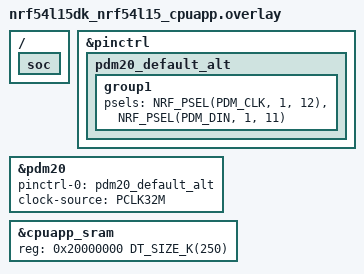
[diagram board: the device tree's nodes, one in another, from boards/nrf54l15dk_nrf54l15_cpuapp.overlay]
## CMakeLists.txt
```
# SPDX-License-Identifier: Apache-2.0

cmake_minimum_required(VERSION 3.20.0)
find_package(Zephyr REQUIRED HINTS $ENV{ZEPHYR_BASE})
project(bap_unicast_server_nrf54l15)

target_sources(app PRIVATE
  src/main.c
  src/ml_main.cc
  src/mfcc_data.c
  src/kws_model_data.cc
  src/cpu_based_blocks.cc
)

zephyr_library_include_directories(${ZEPHYR_BASE}/samples/bluetooth)
```

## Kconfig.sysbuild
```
# Copyright 2023 Nordic Semiconductor ASA
# SPDX-License-Identifier: Apache-2.0

source "share/sysbuild/Kconfig"

config NET_CORE_BOARD
	string
	default "nrf5340dk/nrf5340/cpunet" if "$(BOARD)" = "nrf5340dk"
	default "nrf5340_audio_dk/nrf5340/cpunet" if "$(BOARD)" = "nrf5340_audio_dk"
	default "nrf5340bsim/nrf5340/cpunet" if $(BOARD_TARGET_STRING) = "NRF5340BSIM_NRF5340_CPUAPP"

config NET_CORE_IMAGE_HCI_IPC
	bool "HCI IPC image on network core"
	default y
	depends on NET_CORE_BOARD != ""
```

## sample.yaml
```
sample:
  description: Bluetooth Low Energy Audio Unicast Server sample
  name: Bluetooth Low Energy Audio Unicast Server sample
tests:
  sample.bluetooth.audio_unicast_server:
    harness: bluetooth
    platform_allow:
      - qemu_cortex_m3
      - qemu_x86
      - nrf5340bsim/nrf5340/cpuapp
      - nrf5340dk/nrf5340/cpuapp
      - native_sim
    tags: bluetooth
    integration_platforms:
      - nrf5340dk/nrf5340/cpuapp
    sysbuild: true
  sample.bluetooth.audio_unicast_server.bt_ll_sw_split:
    harness: bluetooth
    platform_allow:
      - nrf52_bsim
      - nrf52dk/nrf52832
      - nrf52840dk/nrf52840
    integration_platforms:
      - nrf52dk/nrf52832
    extra_args:
      - OVERLAY_CONFIG=overlay-bt_ll_sw_split.conf
      - SNIPPET="bt-ll-sw-split"
    tags: bluetooth
```

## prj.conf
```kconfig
CONFIG_AUDIO_DMIC=y
CONFIG_AUDIO=y
CONFIG_BT=y
CONFIG_LOG=y
CONFIG_BT_PERIPHERAL=y
CONFIG_BT_ISO_PERIPHERAL=y
CONFIG_BT_AUDIO=y
CONFIG_BT_BAP_UNICAST_SERVER=y
CONFIG_BT_ASCS=y
CONFIG_BT_ASCS_MAX_ASE_SNK_COUNT=1
CONFIG_BT_ASCS_MAX_ASE_SRC_COUNT=1
CONFIG_BT_ISO_TX_BUF_COUNT=16
# Support an ISO channel per ASE
CONFIG_BT_ISO_MAX_CHAN=2

CONFIG_BT_AUDIO_CODEC_CFG_MAX_METADATA_SIZE=80

# Mandatory to support at least 1 for ASCS
CONFIG_BT_ATT_PREPARE_COUNT=8
CONFIG_BT_GATT_DYNAMIC_DB=y
CONFIG_BT_EXT_ADV=y
CONFIG_BT_DEVICE_NAME="nrf54l15_pdm_mic"
CONFIG_SW_CODEC_LC3_T2_SOFTWARE=y
CONFIG_FPU=y
CONFIG_NEWLIB_LIBC=y
CONFIG_BT_LOG_SNIFFER_INFO=y
CONFIG_THREAD_NAME=y
CONFIG_CLOCK_CONTROL=y
CONFIG_LC3_ENC_CHAN_MAX=1
CONFIG_BT_BONDABLE=y
CONFIG_BT_SMP=y
CONFIG_LOG_BUFFER_SIZE=4096

# Enable DK LED and Buttons library
CONFIG_DK_LIBRARY=y
CONFIG_BT_SECURITY_ERR_TO_STR=y
CONFIG_BT_SMP_ERR_TO_STR=y

CONFIG_BT_MAX_CONN=2
CONFIG_BT_ATT_TX_COUNT=5
CONFIG_BT_BAS=y
CONFIG_BT_HIDS=y
CONFIG_BT_HIDS_MAX_CLIENT_COUNT=2
CONFIG_BT_HIDS_DEFAULT_PERM_RW_ENCRYPT=y
CONFIG_BT_GATT_UUID16_POOL_SIZE=40
CONFIG_BT_GATT_CHRC_POOL_SIZE=20
CONFIG_BT_CONN_CTX=y
CONFIG_BT_DIS=y
CONFIG_BT_DIS_MANUF_NAME=y
CONFIG_BT_DIS_MANUF_NAME_STR="NordicSemiconductor"
CONFIG_BT_DIS_PNP=y
CONFIG_BT_DIS_PNP_VID_SRC=2
CONFIG_BT_DIS_PNP_VID=0x1915
CONFIG_BT_DIS_PNP_PID=0xEEEE
CONFIG_BT_DIS_PNP_VER=0x0100


CONFIG_MAIN_STACK_SIZE=2048
CONFIG_SYSTEM_WORKQUEUE_STACK_SIZE=2048

CONFIG_BT_SETTINGS=y
CONFIG_FLASH=y
CONFIG_FLASH_MAP=y
CONFIG_NVS=y
CONFIG_SETTINGS=y

CONFIG_GPIO=y
```

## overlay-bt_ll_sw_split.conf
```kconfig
CONFIG_BT_LL_SW_SPLIT=y
CONFIG_BT_CTLR_ADV_DATA_LEN_MAX=191
CONFIG_BT_CTLR_ISO_TX_BUFFERS=2
CONFIG_BT_CTLR_ISOAL_SOURCES=1
CONFIG_BT_CTLR_ISOAL_SINKS=2

# Support the highest SDU size required by any BAP LC3 presets (155) + 8 bytes of HCI ISO Data
# packet overhead (the Packet_Sequence_Number, ISO_SDU_Length, Packet_Status_Flag fields; and
# the optional Time_Stamp field, if supplied)
CONFIG_BT_CTLR_ISO_TX_BUFFER_SIZE=163

# Use the below if the sample is sending stale packet sequence number
# CONFIG_BT_CTLR_ADVANCED_FEATURES=y
# CONFIG_BT_CTLR_ISOAL_SN_STRICT=n
```

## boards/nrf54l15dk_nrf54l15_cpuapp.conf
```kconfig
# For LC3 the following configs are needed
CONFIG_FPU=y
#CONFIG_LIBLC3=y
# The LC3 codec uses a large amount of stack. This app runs the codec in the work-queue, hence
# inctease stack size for that thread.
CONFIG_SYSTEM_WORKQUEUE_STACK_SIZE=8192

CONFIG_BT_BUF_EVT_RX_SIZE=255
CONFIG_BT_BUF_ACL_RX_SIZE=255
CONFIG_BT_BUF_ACL_TX_SIZE=251
CONFIG_BT_BUF_CMD_TX_SIZE=255

# KCONFIG for KWS
CONFIG_MAIN_STACK_SIZE=8192
CONFIG_RING_BUFFER=y
CONFIG_CPP=y
CONFIG_STD_CPP17=y
CONFIG_NEWLIB_LIBC=y
CONFIG_REQUIRES_FULL_LIBCPP=y
CONFIG_CBPRINTF_FP_SUPPORT=y
CONFIG_FPU=y
CONFIG_LOG=y
CONFIG_LOG_MODE_IMMEDIATE=y
CONFIG_PRINTK=y
CONFIG_PRINTK_SYNC=y
CONFIG_CMSIS_NN=y
CONFIG_CMSIS_NN_ACTIVATION=y
CONFIG_CMSIS_NN_BASICMATH=y
CONFIG_CMSIS_NN_CONCATENATION=y
CONFIG_CMSIS_NN_CONVOLUTION=y
CONFIG_CMSIS_NN_FULLYCONNECTED=y
CONFIG_CMSIS_NN_NNSUPPORT=y
CONFIG_CMSIS_NN_POOLING=y
CONFIG_CMSIS_NN_RESHAPE=y
CONFIG_CMSIS_NN_SOFTMAX=y
CONFIG_CMSIS_NN_SVD=y
CONFIG_CMSIS_NN_LSTM=y

#enable CMSIS MFCC
CONFIG_FPU=y
CONFIG_CMSIS_DSP=y
CONFIG_CMSIS_DSP_BASICMATH=y
CONFIG_CMSIS_DSP_COMPLEXMATH=y
CONFIG_CMSIS_DSP_FASTMATH=y
CONFIG_CMSIS_DSP_FILTERING=y
CONFIG_CMSIS_DSP_MATRIX=y
CONFIG_CMSIS_DSP_STATISTICS=y
CONFIG_CMSIS_DSP_TRANSFORM=y
CONFIG_CMSIS_DSP_DISTANCE=y
CONFIG_CMSIS_DSP_WINDOW=y

CONFIG_CMSIS_DSP_LOOPUNROLL=y

CONFIG_REQUIRES_FLOAT_PRINTF=y

CONFIG_TENSORFLOW_LITE_MICRO=y
CONFIG_TENSORFLOW_LITE_MICRO_CMSIS_NN_KERNELS=y
```

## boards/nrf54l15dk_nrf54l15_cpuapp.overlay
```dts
/*
 * Copyright (c) 2024 Nordic Semiconductor ASA
 *
 * SPDX-License-Identifier: Apache-2.0
 */

&pinctrl {
	pdm20_default_alt: pdm20_default_alt {
		group1 {
			psels = <NRF_PSEL(PDM_CLK, 1, 12)>,
				<NRF_PSEL(PDM_DIN, 1, 11)>;
		};
	};
};

dmic_dev: &pdm20 {
	status = "okay";
	pinctrl-0 = <&pdm20_default_alt>;
	pinctrl-names = "default";
	clock-source = "PCLK32M";
};

&cpuapp_sram {
	reg = <0x20000000 DT_SIZE_K(250)>;
	ranges = <0x0 0x20000000 DT_SIZE_K(250)>;
};

/{
	soc {
		/delete-node/ cpuflpr_sram;
	};

};
```

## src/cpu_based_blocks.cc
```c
#include <zephyr/kernel.h>
#include <stdio.h>
#include <string.h>
#include <stdarg.h>

#include <dsp/transform_functions.h>
#include <dsp/statistics_functions.h>
#include <dsp/basic_math_functions.h>
#include <dsp/complex_math_functions.h>
#include <dsp/fast_math_functions.h>
#include <dsp/matrix_functions.h>
#include "mfcc_data.h"

#include <tensorflow/lite/micro/micro_mutable_op_resolver.h>
#include <tensorflow/lite/micro/micro_log.h>
#include <tensorflow/lite/micro/micro_interpreter.h>
#include <tensorflow/lite/micro/system_setup.h>
#include <tensorflow/lite/schema/schema_generated.h>
#include "kws_model_data.h"

#include <zephyr/logging/log.h>
#define LOG_LEVEL 2
LOG_MODULE_DECLARE(dmic_sample);


#include <math.h>

static arm_mfcc_instance_f32 S_mfcc;
static float cmsis_mfcc_input[512]; // hold mfcc input
float cmsis_mfcc_tmp[1024]; // tmp buffer to mfcc

const tflite::Model *model = nullptr;
tflite::MicroInterpreter *interpreter = nullptr;
TfLiteTensor *input = nullptr;
TfLiteTensor *output = nullptr;
float input_scale, output_scale;
int input_zp, output_zp;
constexpr int kTensorArenaSize = 30000;
uint8_t tensor_arena[kTensorArenaSize];



inline void arm_mfcc_f32_modified(
	const arm_mfcc_instance_f32 * S,
	float32_t *pSrc,
	float32_t *pDst,
	float32_t *pTmp
	)
{

	// float32_t maxValue;
	// uint32_t  index;
	uint32_t i;
	float32_t result;
	const float32_t *coefs=S->filterCoefs;
	arm_matrix_instance_f32 pDctMat;

	/* Normalize */
	// arm_absmax_f32(pSrc,S->fftLen,&maxValue,&index);

	// if (maxValue != 0.0f)
	// {
	//    arm_scale_f32(pSrc,1.0f/maxValue,pSrc,S->fftLen);
	// }

	/* Multiply by window */
	arm_mult_f32(pSrc,S->windowCoefs,pSrc,S->fftLen);

	/* Compute spectrum magnitude
	*/
#if defined(ARM_MFCC_CFFT_BASED)
	/* some HW accelerator for CMSIS-DSP used in some boards
		are only providing acceleration for CFFT.
		With ARM_MFCC_CFFT_BASED enabled, CFFT is used and the MFCC
		will be accelerated on those boards.

		The default is to use RFFT
	*/
	/* Convert from real to complex */
	for(i=0; i < S->fftLen ; i++)
	{
		pTmp[2*i] = pSrc[i];
		pTmp[2*i+1] = 0.0f;
	}
	arm_cfft_f32(&(S->cfft),pTmp,0,1);
#else
	/* Default RFFT based implementation */
	arm_rfft_fast_f32(&(S->rfft),pSrc,pTmp,0);
	/* Unpack real values */
	pTmp[S->fftLen]=pTmp[1];
	pTmp[S->fftLen+1]=0.0f;
	pTmp[1]=0.0f;
#endif
	// Shouldn't the length be S->fftLen + 2 (=514) or 257 complex points ?
	arm_cmplx_mag_f32(pTmp,pSrc,(S->fftLen + 2)/2);
	// if (maxValue != 0.0f)
	// {
	//    arm_scale_f32(pSrc,maxValue,pSrc,S->fftLen);
	// }

	/* Apply MEL filters */
	for(i=0; i<S->nbMelFilters; i++)
	{
		arm_dot_prod_f32(pSrc+S->filterPos[i],
			coefs,
			S->filterLengths[i],
			&result);

		coefs += S->filterLengths[i];

		pTmp[i] = result;

	}

	/* Compute the log */
	arm_offset_f32(pTmp,1.0e-6f,pTmp,S->nbMelFilters);
	arm_vlog_f32(pTmp,pTmp,S->nbMelFilters);

	/* Multiply with the DCT matrix */
	pDctMat.numRows=S->nbDctOutputs;
	pDctMat.numCols=S->nbMelFilters;
	pDctMat.pData=(float32_t*)S->dctCoefs;

	arm_mat_vec_mult_f32(&pDctMat, pTmp, pDst);
}




int cpu_blocks_init(void) {
	uint32_t start, end;


	arm_mfcc_init_f32(&S_mfcc,
		512,
		40,
		10,
		mfcc_dct_coefs_config1_f32,
		mfcc_filter_pos_config1_f32,
		mfcc_filter_len_config1_f32,
		mfcc_filter_coefs_config1_f32,
		mfcc_window_coefs_config1_f32);

	model = tflite::GetModel(kws_model_data);
	if (model->version() != TFLITE_SCHEMA_VERSION) {
		MicroPrintf("Model provided is schema version %d not equal "
					"to supported version %d.",
					model->version(), TFLITE_SCHEMA_VERSION);
		return 1;
	}
	static tflite::MicroMutableOpResolver <6> micro_op_resolver;
	micro_op_resolver.AddFullyConnected();
    micro_op_resolver.AddAveragePool2D();
    micro_op_resolver.AddConv2D();
    micro_op_resolver.AddDepthwiseConv2D();
    micro_op_resolver.AddReshape();
    micro_op_resolver.AddSoftmax();

	static tflite::MicroInterpreter static_interpreter(
		model, micro_op_resolver, tensor_arena, kTensorArenaSize);
	interpreter = &static_interpreter;

	/* Allocate memory from the tensor_arena for the model's tensors. */
	TfLiteStatus allocate_status = interpreter->AllocateTensors();
	if (allocate_status != kTfLiteOk) {
		MicroPrintf("AllocateTensors() failed");
		return 1;
	}

	/* Obtain pointers to the model's input and output tensors. */
	input = interpreter->input(0);
	output = interpreter->output(0);



	input_scale = ((TfLiteAffineQuantization*)input->quantization.params)->scale->data[0];
	input_zp = ((TfLiteAffineQuantization*)input->quantization.params)->zero_point->data[0];

	output_scale = ((TfLiteAffineQuantization*)output->quantization.params)->scale->data[0];
	output_zp = ((TfLiteAffineQuantization*)output->quantization.params)->zero_point->data[0];

	printk("input tensor quant spec: zero point = %d, scale = %f\n", input_zp, input_scale);
	printk("output tensor quant spec: zero point = %d, scale = %f\n", output_zp, output_scale);

	return 0;
}

void mfcc_cpu(const int16_t* audio_sample, int8_t* mfcc_result) {
    float mfcc_slice[10];

	for (int i = 0; i < 480; i++) {
		cmsis_mfcc_input[i] = audio_sample[i] / 32768.0f;
	}
	arm_mfcc_f32_modified(&S_mfcc, cmsis_mfcc_input, mfcc_slice, cmsis_mfcc_tmp);

	/* Quantize based on input tensor spec */
	for (int j = 0; j < 10; j++) {
		int32_t tmp;
		// tmp = static_cast<int32_t>(mfcc_slice[j] / input_scale) + input_zp;
		tmp = static_cast<int32_t>(round(mfcc_slice[j] / input_scale)) + input_zp;
		if (tmp > INT8_MAX) {
			mfcc_result[j] = INT8_MAX;
			LOG_INF("too large! %d\n", tmp);
		} else if (tmp < INT8_MIN) {
			mfcc_result[j] = INT8_MIN;
			LOG_INF("too small! %d\n", tmp);
		} else {
			mfcc_result[j] = static_cast<int8_t>(tmp);
		}
	}

}

void inference_cpu(const int8_t* mfcc_feature_map, int* class_index) {

	uint32_t start, end;
	start = k_uptime_get_32();
	TfLiteStatus invoke_status = kTfLiteOk;

	for (int i = 0; i < 490; i++) {
		(input->data.int8)[i] = mfcc_feature_map[i];
	}

	invoke_status = interpreter->Invoke();
	end = k_uptime_get_32();
	// printk("Time used for inference: %d ms.\n", end - start);
	if (invoke_status != kTfLiteOk) {
		printk("Invoke failed\n");
		return;
	}

	/* Retrieve result */
	int max_idx = 0;
	for (int i = 0; i < 12; i++) {
		if (output->data.int8[max_idx] < output->data.int8[i]) {
			max_idx = i;
		}
	}
	*class_index = max_idx;

	return;
}
```

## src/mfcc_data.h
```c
#ifndef _MFCC_DATA_H_
#define _MFCC_DATA_H_ 

#include "arm_math_types.h"


#ifdef   __cplusplus
extern "C"
{
#endif


/*****

 DCT COEFFICIENTS FOR THE MFCC

*****/


#define NB_MFCC_DCT_COEFS_CONFIG1_F32 400
extern const float32_t mfcc_dct_coefs_config1_f32[NB_MFCC_DCT_COEFS_CONFIG1_F32];



/*****

 WINDOW COEFFICIENTS

*****/


#define NB_MFCC_WIN_COEFS_CONFIG1_F32 512
extern const float32_t mfcc_window_coefs_config1_f32[NB_MFCC_WIN_COEFS_CONFIG1_F32];



/*****

 MEL FILTER COEFFICIENTS FOR THE MFCC

*****/

#define NB_MFCC_NB_FILTER_CONFIG1_F32 40
extern const uint32_t mfcc_filter_pos_config1_f32[NB_MFCC_NB_FILTER_CONFIG1_F32];
extern const uint32_t mfcc_filter_len_config1_f32[NB_MFCC_NB_FILTER_CONFIG1_F32];





#define NB_MFCC_FILTER_COEFS_CONFIG1_F32 247
extern const float32_t mfcc_filter_coefs_config1_f32[NB_MFCC_FILTER_COEFS_CONFIG1_F32];



#ifdef   __cplusplus
}
#endif

#endif
```

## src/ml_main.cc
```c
#include <zephyr/kernel.h>
#include <stdio.h>
#include <string.h>
#include <stdarg.h>
#include <zephyr/sys/ring_buffer.h>
#include <math.h>
#include <dk_buttons_and_leds.h>

#include "ml_main.h"

#define SAMPLE_LENGTH_IN_MS 100
#define PDM_BYTE_DEPTH 2
#define PDM_SAMPLE_PER_SEC 16000

extern void cpu_blocks_init(void);
extern void mfcc_cpu(const int16_t* audio_sample, int8_t* mfcc_result);
extern void inference_cpu(const int8_t* mfcc_feature_map, int* class_index);



#define MFCC_STEP_IN_MS 20
#define MFCC_WINDOW_IN_MS 30

/*
 * Local buffer to copy data from PDM buffer. Extra space for data corrsponding one MFCC window
 * is added to hold residual part
 */

static int16_t mfcc_input[PDM_SAMPLE_PER_SEC*SAMPLE_LENGTH_IN_MS/MSEC_PER_SEC+PDM_SAMPLE_PER_SEC*MFCC_WINDOW_IN_MS/MSEC_PER_SEC];


#define MFCC_RING_BUF_BYTES 1000
RING_BUF_DECLARE(mfcc_int8_ring_buf, MFCC_RING_BUF_BYTES);

/* Semephore to sync mfcc calculation and kws inference. */
/* It's binary as we let the inference workflow to determine how many rounds of inference should happen */
K_SEM_DEFINE(mfcc_ready, 0 ,1);

#define MFCC_DATA_LENGTH 10
#define KWS_MFCC_WINDOW 49
#define KWS_MFCC_STEP 10
int8_t inference_input[KWS_MFCC_WINDOW*MFCC_DATA_LENGTH];

const char* label[] = {"Down", "Go", "Left", "No", "Off", "On", "Right", "Stop", "Up", "Yes", "Silence", "Unknown"};

#define INFERENCE_STACK_SIZE 4096
#define INFERENCE_PRIORITY 5

void inference_thread(void *, void *, void *) {
#define FILTER_WINDOW_LEN 4
	int last_n_results[FILTER_WINDOW_LEN];
	for (int i = 0; i < FILTER_WINDOW_LEN; i++) {
				last_n_results[i] = -1;
	}
	while (true) {

		k_sem_take(&mfcc_ready, K_FOREVER);
		while (ring_buf_size_get(&mfcc_int8_ring_buf) >= MFCC_DATA_LENGTH * KWS_MFCC_WINDOW) {
			int max_idx = 0;
			ring_buf_peek(&mfcc_int8_ring_buf, (uint8_t*)inference_input, MFCC_DATA_LENGTH * KWS_MFCC_WINDOW);


			inference_cpu(inference_input, &max_idx);



			// printk("[%u] Label: %s, likelihood %f\n",end, label[max_idx],
			// 	output_scale * (output->data.int8[max_idx] - output_zp));
			for (int i = 0; i < FILTER_WINDOW_LEN - 1; i++) {
				last_n_results[i] = last_n_results[i+1];
			}
			last_n_results[FILTER_WINDOW_LEN - 1] = max_idx;
			bool all_same = true;
			for (int i = 0; i < FILTER_WINDOW_LEN - 1; i++) {
				if (last_n_results[i] != last_n_results[i+1]) {
					all_same = false;
					break;
				}
			}
			if (all_same == true) {
				printk("Label: %s in last %d inferences.\n", label[max_idx], FILTER_WINDOW_LEN);
				if (max_idx == 4) {
					dk_set_led_off(DK_LED4);
				}
				if (max_idx == 5) {
					dk_set_led_on(DK_LED4);
				}
				for (int i = 0; i < FILTER_WINDOW_LEN; i++) {
					last_n_results[i] = -1;
				}
			}

			/* How many data we remove determines how frequency the inference is */
			/* Every step length of 1 equal to 20 ms */
			ring_buf_get(&mfcc_int8_ring_buf, NULL, KWS_MFCC_STEP*MFCC_DATA_LENGTH);

		}

	}

}

K_THREAD_STACK_DEFINE(inference_stack_area, INFERENCE_STACK_SIZE);
struct k_thread inference_thread_data;

uint32_t mfcc_input_tail;

int ml_init(void) {
	cpu_blocks_init();

	/*start inference thread*/
	k_tid_t my_tid = k_thread_create(&inference_thread_data, inference_stack_area,
                                 K_THREAD_STACK_SIZEOF(inference_stack_area),
                                 inference_thread,
                                 NULL, NULL, NULL,
                                 INFERENCE_PRIORITY, 0, K_NO_WAIT);
	printk("inference thread id %d\n", my_tid);

	mfcc_input_tail = 0;
	return 0;
}
int ml_process(void* buffer, size_t size) {


	int sample_len;

	sample_len = size / 2;

	for (int i = 0; i < sample_len; i++) {
		mfcc_input[mfcc_input_tail] = ((int16_t*)buffer)[i];
		mfcc_input_tail++;
	}

	uint32_t start, end;
	// Calculate MFCC feature map
	start = k_uptime_get_32();

	int number_of_windows = (mfcc_input_tail - (PDM_SAMPLE_PER_SEC*MFCC_WINDOW_IN_MS/MSEC_PER_SEC)
		+ (PDM_SAMPLE_PER_SEC*MFCC_STEP_IN_MS/MSEC_PER_SEC)) / (PDM_SAMPLE_PER_SEC*MFCC_STEP_IN_MS/MSEC_PER_SEC);
		for (int i = 0; i < number_of_windows; i++) {

		int8_t mfcc_slice_int8[MFCC_DATA_LENGTH];

		mfcc_cpu(&(mfcc_input[PDM_SAMPLE_PER_SEC*MFCC_STEP_IN_MS/MSEC_PER_SEC*i]), mfcc_slice_int8);



		uint32_t ret;

		ret = ring_buf_put(&mfcc_int8_ring_buf, (const uint8_t*)mfcc_slice_int8, sizeof(mfcc_slice_int8));
		if (ret != sizeof(mfcc_slice_int8)) {
			printk("Ring buffer full!, queued %d, expected 10\n", ret);
			/* The return value is not checked because there should be enough data to discard */
			// ring_buf_get(&mfcc_int8_ring_buf, NULL, 10 - ret);
			// ring_buf_put(&mfcc_int8_ring_buf, (const uint8_t*)&(mfcc_slice_int8[ret]), 10 - ret);
		}
	}
	end = k_uptime_get_32();
	// printk("Time used for %d mfcc calculation: %d ms.\n", number_of_windows, end - start);
	for (uint32_t i = 0; i < mfcc_input_tail - PDM_SAMPLE_PER_SEC*MFCC_STEP_IN_MS/MSEC_PER_SEC * number_of_windows; i++) {
		mfcc_input[i] = mfcc_input[PDM_SAMPLE_PER_SEC*MFCC_STEP_IN_MS/MSEC_PER_SEC * number_of_windows + i];
	}
	mfcc_input_tail = mfcc_input_tail - PDM_SAMPLE_PER_SEC*MFCC_STEP_IN_MS/MSEC_PER_SEC * number_of_windows;

	/* Trigger inference here */
	if (ring_buf_size_get(&mfcc_int8_ring_buf) >= MFCC_DATA_LENGTH * KWS_MFCC_WINDOW) {
		k_sem_give(&mfcc_ready);
	}
	return 0;
}
```
